# ioam3358 register map
Registers are 32-bit, access not given, no defined reset value unless marked. A register's access mark holds for its fields unless they carry their own. Addresses are absolute; registers are grouped by the start of their names; [hi:lo] are bit positions; {n}, {i} and the like mark numbered series; 'fields as' and 'values as' point back to an identical list.

## ECAP0
0x48300100 ECAP0_TSCTR
0x48300104 ECAP0_CTRPHS
{0x48300104+4i} ECAP0_CAP{i} (i=1..4)
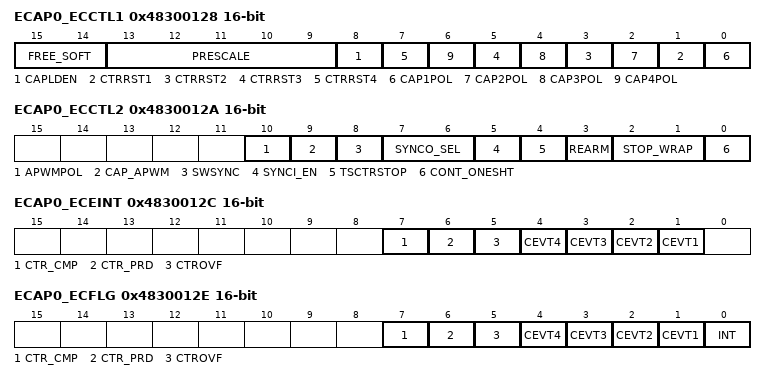
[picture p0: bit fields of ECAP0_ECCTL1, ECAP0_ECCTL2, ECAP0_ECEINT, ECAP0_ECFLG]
0x48300128 ECAP0_ECCTL1 16-bit
  [15:14] FREE_SOFT, [13:9] PRESCALE, [8] CAPLDEN, [2n-1] CTRRST{n} (n=1..4), [2n-2] CAP{n}POL (n=1..4)
0x4830012A ECAP0_ECCTL2 16-bit
  [10] APWMPOL, [9] CAP_APWM, [8] SWSYNC, [7:6] SYNCO_SEL, [5] SYNCI_EN, [4] TSCTRSTOP, [3] REARM, [2:1] STOP_WRAP, [0] CONT_ONESHT
0x4830012C ECAP0_ECEINT 16-bit
  [7] CTR_CMP, [6] CTR_PRD, [5] CTROVF, [n] CEVT{n} (n=1..4)
0x4830012E ECAP0_ECFLG 16-bit
  [7] CTR_CMP, [6] CTR_PRD, [5] CTROVF, [n] CEVT{n} (n=1..4), [0] INT
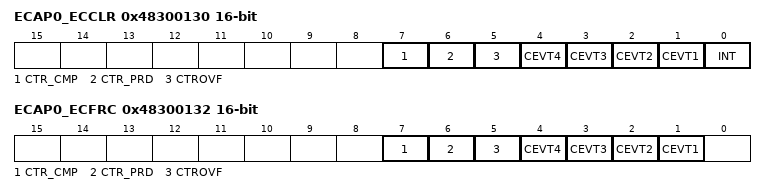
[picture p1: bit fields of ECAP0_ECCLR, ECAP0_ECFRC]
0x48300130 ECAP0_ECCLR 16-bit
  [7] CTR_CMP, [6] CTR_PRD, [5] CTROVF, [n] CEVT{n} (n=1..4), [0] INT
0x48300132 ECAP0_ECFRC 16-bit
  [7] CTR_CMP, [6] CTR_PRD, [5] CTROVF, [n] CEVT{n} (n=1..4)
0x4830015C ECAP0_REVID

## ECAP1
0x48302100 ECAP1_TSCTR
0x48302104 ECAP1_CTRPHS
{0x48302104+4i} ECAP1_CAP{i} (i=1..4)
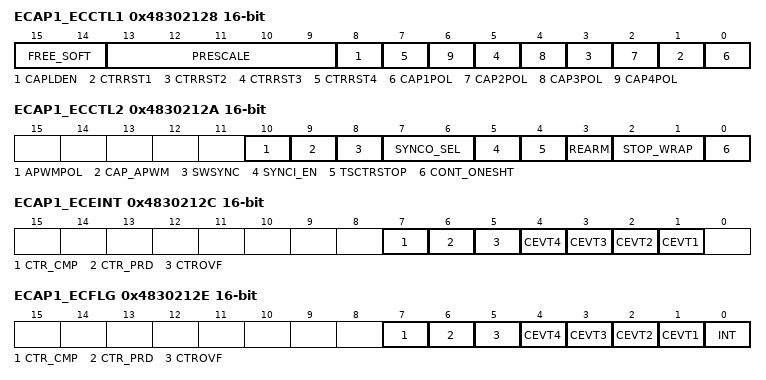
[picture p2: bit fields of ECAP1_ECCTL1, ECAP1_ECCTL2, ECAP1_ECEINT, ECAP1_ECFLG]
0x48302128 ECAP1_ECCTL1 16-bit
  [15:14] FREE_SOFT, [13:9] PRESCALE, [8] CAPLDEN, [2n-1] CTRRST{n} (n=1..4), [2n-2] CAP{n}POL (n=1..4)
0x4830212A ECAP1_ECCTL2 16-bit
  [10] APWMPOL, [9] CAP_APWM, [8] SWSYNC, [7:6] SYNCO_SEL, [5] SYNCI_EN, [4] TSCTRSTOP, [3] REARM, [2:1] STOP_WRAP, [0] CONT_ONESHT
0x4830212C ECAP1_ECEINT 16-bit
  [7] CTR_CMP, [6] CTR_PRD, [5] CTROVF, [n] CEVT{n} (n=1..4)
0x4830212E ECAP1_ECFLG 16-bit
  [7] CTR_CMP, [6] CTR_PRD, [5] CTROVF, [n] CEVT{n} (n=1..4), [0] INT
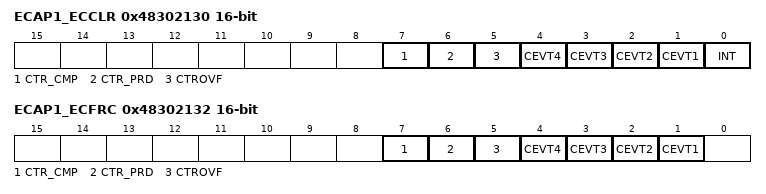
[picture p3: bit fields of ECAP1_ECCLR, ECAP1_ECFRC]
0x48302130 ECAP1_ECCLR 16-bit
  [7] CTR_CMP, [6] CTR_PRD, [5] CTROVF, [n] CEVT{n} (n=1..4), [0] INT
0x48302132 ECAP1_ECFRC 16-bit
  [7] CTR_CMP, [6] CTR_PRD, [5] CTROVF, [n] CEVT{n} (n=1..4)
0x4830215C ECAP1_REVID

## ECAP2
0x48304100 ECAP2_TSCTR
0x48304104 ECAP2_CTRPHS
{0x48304104+4i} ECAP2_CAP{i} (i=1..4)
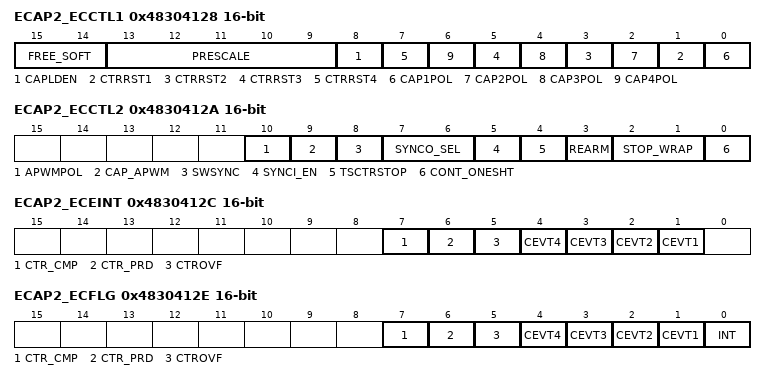
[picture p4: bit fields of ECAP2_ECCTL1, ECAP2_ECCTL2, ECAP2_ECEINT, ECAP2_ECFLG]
0x48304128 ECAP2_ECCTL1 16-bit
  [15:14] FREE_SOFT, [13:9] PRESCALE, [8] CAPLDEN, [2n-1] CTRRST{n} (n=1..4), [2n-2] CAP{n}POL (n=1..4)
0x4830412A ECAP2_ECCTL2 16-bit
  [10] APWMPOL, [9] CAP_APWM, [8] SWSYNC, [7:6] SYNCO_SEL, [5] SYNCI_EN, [4] TSCTRSTOP, [3] REARM, [2:1] STOP_WRAP, [0] CONT_ONESHT
0x4830412C ECAP2_ECEINT 16-bit
  [7] CTR_CMP, [6] CTR_PRD, [5] CTROVF, [n] CEVT{n} (n=1..4)
0x4830412E ECAP2_ECFLG 16-bit
  [7] CTR_CMP, [6] CTR_PRD, [5] CTROVF, [n] CEVT{n} (n=1..4), [0] INT
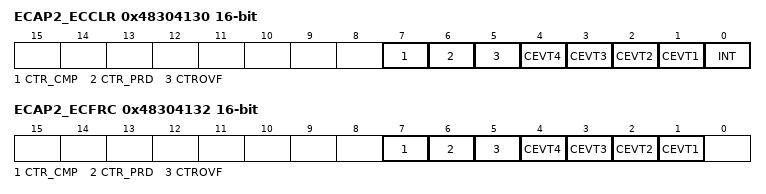
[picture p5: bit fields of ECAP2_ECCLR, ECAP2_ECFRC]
0x48304130 ECAP2_ECCLR 16-bit
  [7] CTR_CMP, [6] CTR_PRD, [5] CTROVF, [n] CEVT{n} (n=1..4), [0] INT
0x48304132 ECAP2_ECFRC 16-bit
  [7] CTR_CMP, [6] CTR_PRD, [5] CTROVF, [n] CEVT{n} (n=1..4)
0x4830415C ECAP2_REVID

## EQEP0
0x48300180 EQEP0_QPOSCNT
0x48300184 EQEP0_QPOSINIT
0x48300188 EQEP0_QPOSMAX
0x4830018C EQEP0_QPOSCMP
0x48300190 EQEP0_QPOSILAT
0x48300194 EQEP0_QPOSSLAT
0x48300198 EQEP0_QPOSLAT
0x4830019C EQEP0_QUTMR
0x483001A0 EQEP0_QUPRD
0x483001A4 EQEP0_QWDTMR 16-bit
0x483001A6 EQEP0_QWDPRD 16-bit
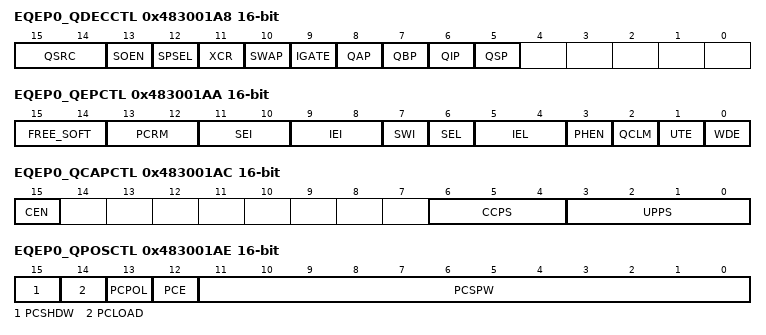
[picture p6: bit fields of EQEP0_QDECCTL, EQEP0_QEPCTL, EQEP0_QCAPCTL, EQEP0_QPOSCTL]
0x483001A8 EQEP0_QDECCTL 16-bit
  [15:14] QSRC, [13] SOEN, [12] SPSEL, [11] XCR, [10] SWAP, [9] IGATE, [8] QAP, [7] QBP, [6] QIP, [5] QSP
0x483001AA EQEP0_QEPCTL 16-bit
  [15:14] FREE_SOFT, [13:12] PCRM, [11:10] SEI, [9:8] IEI, [7] SWI, [6] SEL, [5:4] IEL, [3] PHEN, [2] QCLM, [1] UTE, [0] WDE
0x483001AC EQEP0_QCAPCTL 16-bit
  [15] CEN, [6:4] CCPS, [3:0] UPPS
0x483001AE EQEP0_QPOSCTL 16-bit
  [15] PCSHDW, [14] PCLOAD, [13] PCPOL, [12] PCE, [11:0] PCSPW
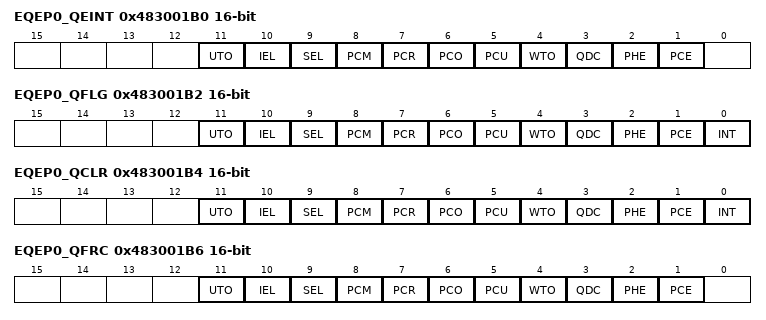
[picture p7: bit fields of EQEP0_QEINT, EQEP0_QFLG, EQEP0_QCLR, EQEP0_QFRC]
0x483001B0 EQEP0_QEINT 16-bit
  [11] UTO, [10] IEL, [9] SEL, [8] PCM, [7] PCR, [6] PCO, [5] PCU, [4] WTO, [3] QDC, [2] PHE, [1] PCE
0x483001B2 EQEP0_QFLG 16-bit
  [11] UTO, [10] IEL, [9] SEL, [8] PCM, [7] PCR, [6] PCO, [5] PCU, [4] WTO, [3] QDC, [2] PHE, [1] PCE, [0] INT
0x483001B4 EQEP0_QCLR 16-bit
  fields as EQEP0_QFLG
0x483001B6 EQEP0_QFRC 16-bit
  fields as EQEP0_QEINT
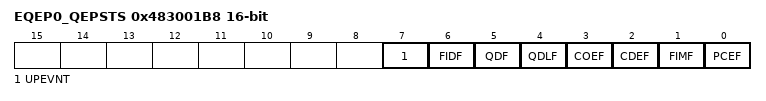
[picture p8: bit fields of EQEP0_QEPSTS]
0x483001B8 EQEP0_QEPSTS 16-bit
  [7] UPEVNT, [6] FIDF, [5] QDF, [4] QDLF, [3] COEF, [2] CDEF, [1] FIMF, [0] PCEF
0x483001BA EQEP0_QCTMR 16-bit
0x483001BC EQEP0_QCPRD 16-bit
0x483001BE EQEP0_QCTMRLAT 16-bit
0x483001C0 EQEP0_QCPRDLAT 16-bit
0x483001DC EQEP0_REVID 16-bit
